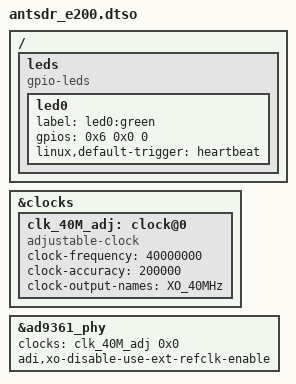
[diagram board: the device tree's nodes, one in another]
/dts-v1/;
/plugin/;

/ {
    // Add board specific clocks
    fragment@0{
       target = <&clocks>;
       __overlay__{
           clk_40M_adj: clock@0 {
               #clock-cells = <0>;
               compatible = "adjustable-clock";
               clock-frequency = <40000000>;
               clock-accuracy = <200000>;
               clock-output-names = "XO_40MHz";
           };
       };
    };

    // Set clock in ad9361_phy
    fragment@1{
       target = <&ad9361_phy>;
       __overlay__{
           clocks = <&clk_40M_adj 0x0>;
           adi,xo-disable-use-ext-refclk-enable;
       };
    };

    // Insert leds
    fragment@2{
        target-path= "/";
        __overlay__{
            leds {
                compatible = "gpio-leds";

                led0 {
                    label = "led0:green";
                    gpios = <0x6 0x0 0>;
                    linux,default-trigger = "heartbeat";
                };
            };
        };
    };
};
